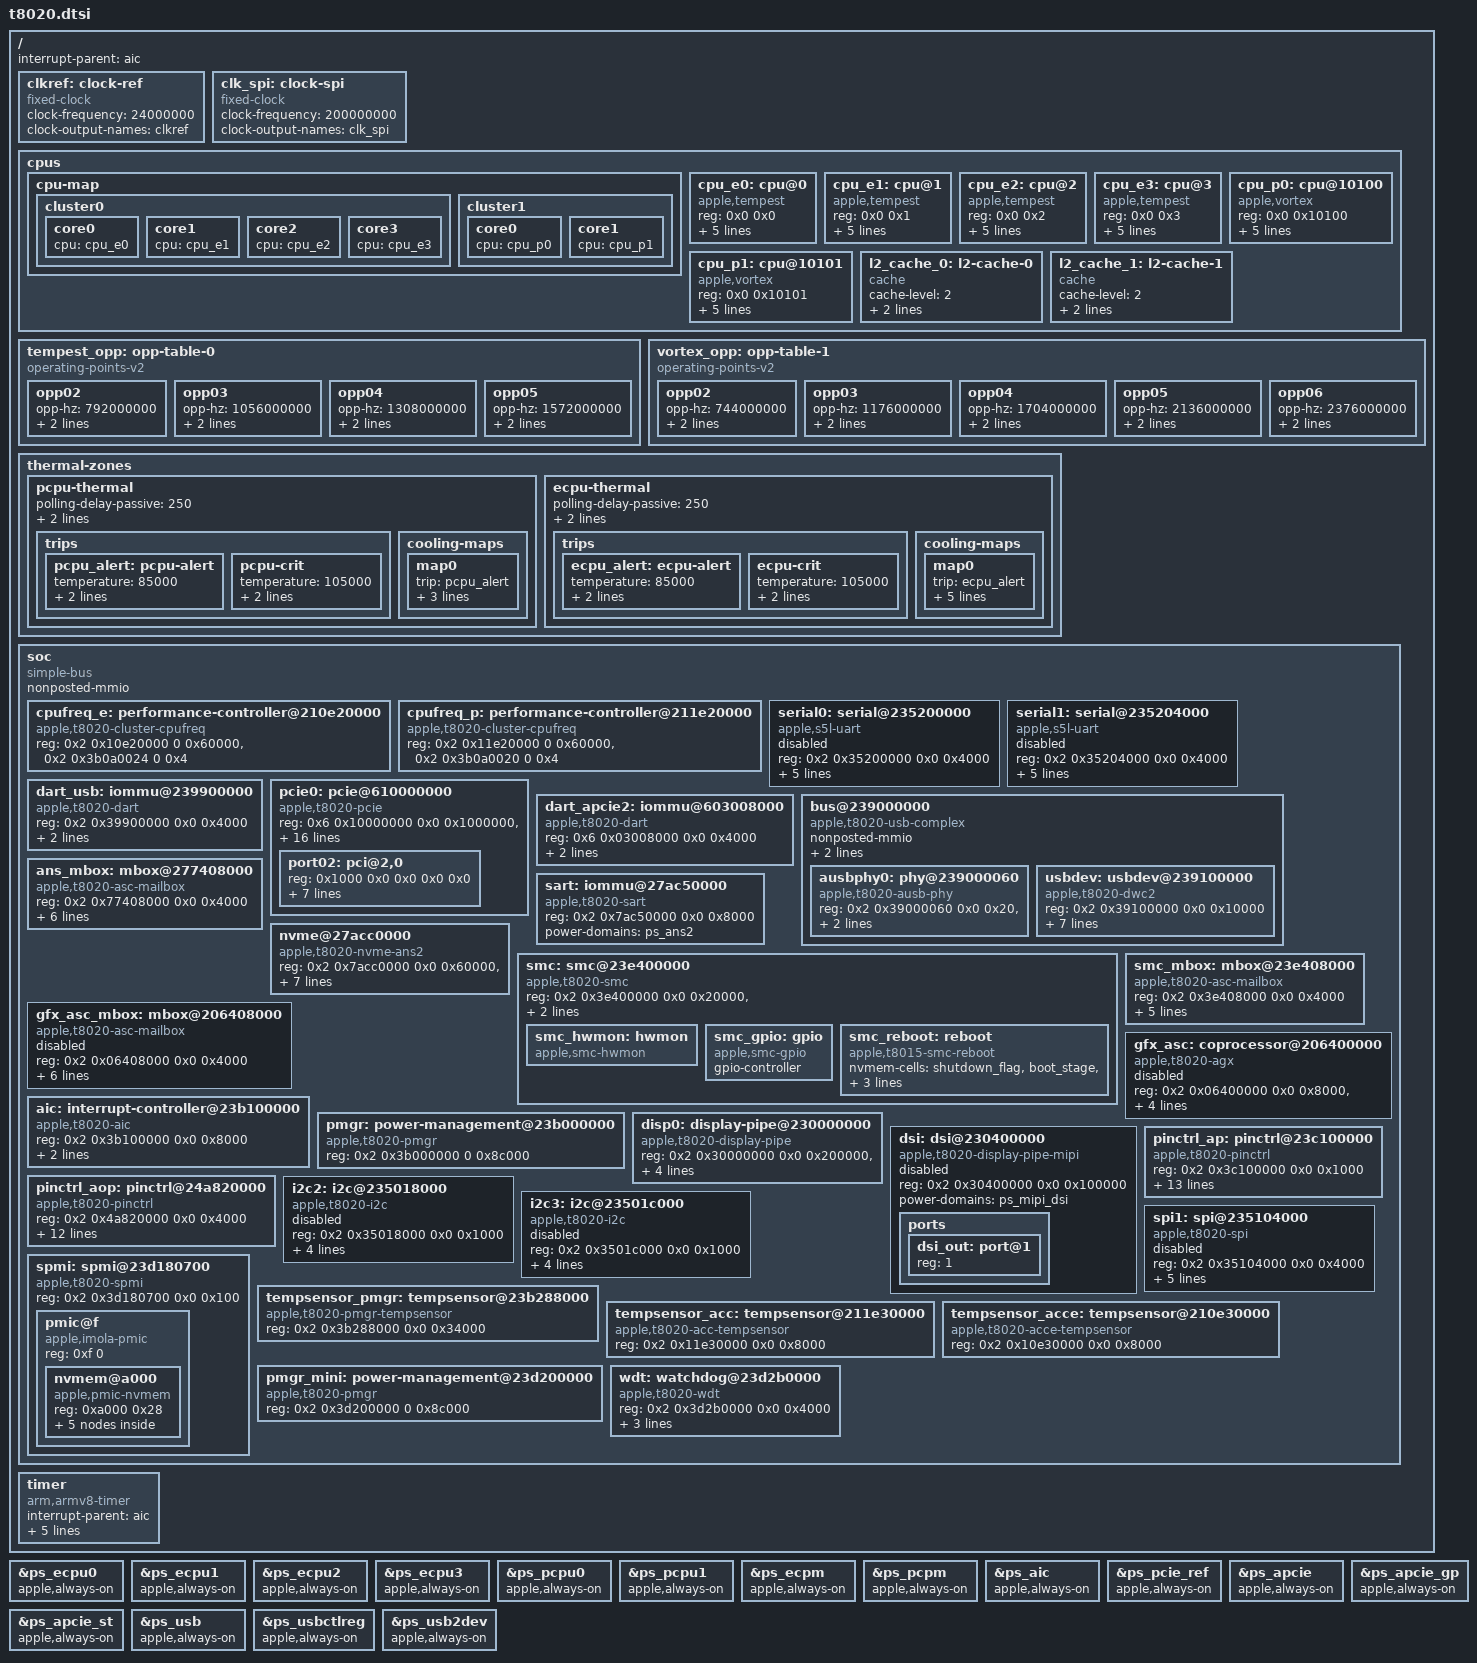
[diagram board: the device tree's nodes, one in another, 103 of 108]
// SPDX-License-Identifier: GPL-2.0+ OR MIT
/*
 * Apple T8020 "A12" SoC
 *
 * Other names: H11
 *
 * Every address and interrupt number here was read out of the DeviceTree
 * shipped in the iPhone11,2 IPSW (see docs/soc.md), not
 * guessed from T8015.
 * The arm-io ranges property maps child 0x0 to parent 0x200000000, so a
 * peripheral offset of 0x35200000 is absolute address 0x235200000.
 *
 * This is a bring-up subset: enough for a console, a shell and the pieces
 * being worked on, nothing more.
 *
 * Copyright (c) 2026, kiki <kieran@lavato.net>
 */

#include <dt-bindings/interrupt-controller/apple-aic.h>
#include <dt-bindings/interrupt-controller/irq.h>
#include <dt-bindings/phy/phy.h>
#include <dt-bindings/thermal/thermal.h>

/ {
	interrupt-parent = <&aic>;
	#address-cells = <2>;
	#size-cells = <2>;

	clkref: clock-ref {
		compatible = "fixed-clock";
		#clock-cells = <0>;
		clock-frequency = <24000000>;
		clock-output-names = "clkref";
	};

	/*
	 * The SPI blocks' input clock. The ADT gives it as clock-ids 362,
	 * which does not resolve to anything in the pmgr clock list, so this
	 * is M1's rate for the same block at the same address. If the real
	 * clock is slower the bus just runs slower than asked, never faster.
	 */
	clk_spi: clock-spi {
		compatible = "fixed-clock";
		#clock-cells = <0>;
		clock-frequency = <200000000>;
		clock-output-names = "clk_spi";
	};

	cpus {
		#address-cells = <2>;
		#size-cells = <0>;

		cpu-map {
			cluster0 {
				core0 {
					cpu = <&cpu_e0>;
				};
				core1 {
					cpu = <&cpu_e1>;
				};
				core2 {
					cpu = <&cpu_e2>;
				};
				core3 {
					cpu = <&cpu_e3>;
				};
			};

			cluster1 {
				core0 {
					cpu = <&cpu_p0>;
				};
				core1 {
					cpu = <&cpu_p1>;
				};
			};
		};

		/*
		 * These must equal MPIDR_EL1 & 0xFFFFFF, which is what m1n1's
		 * dt_set_cpus matches against, and get it wrong and m1n1 refuses
		 * to boot at all ("FDT: DT CPU 0 MPIDR mismatch: 0x10000 != 0x0").
		 * The ADT's reg is not that value. It reports 0 to 3 for the
		 * E cores and 256 and 257 for the P cores, while the hardware
		 * reads 0x0 to 0x3 and 0x10100 and 0x10101: the P cluster
		 * carries Aff2 as well as Aff1, the same scheme as M1. Read with
		 * the m1n1 proxy and from m1n1's own handoff log.
		 */
		cpu_e0: cpu@0 {
			compatible = "apple,tempest";
			reg = <0x0 0x0>;
			cpu-release-addr = <0 0>; /* To be filled by loader */
			performance-domains = <&cpufreq_e>;
			operating-points-v2 = <&tempest_opp>;
			#cooling-cells = <2>;
			enable-method = "spin-table";
			device_type = "cpu";
			next-level-cache = <&l2_cache_0>;
		};

		cpu_e1: cpu@1 {
			compatible = "apple,tempest";
			reg = <0x0 0x1>;
			cpu-release-addr = <0 0>; /* To be filled by loader */
			performance-domains = <&cpufreq_e>;
			operating-points-v2 = <&tempest_opp>;
			#cooling-cells = <2>;
			enable-method = "spin-table";
			device_type = "cpu";
			next-level-cache = <&l2_cache_0>;
		};

		cpu_e2: cpu@2 {
			compatible = "apple,tempest";
			reg = <0x0 0x2>;
			cpu-release-addr = <0 0>; /* To be filled by loader */
			performance-domains = <&cpufreq_e>;
			operating-points-v2 = <&tempest_opp>;
			#cooling-cells = <2>;
			enable-method = "spin-table";
			device_type = "cpu";
			next-level-cache = <&l2_cache_0>;
		};

		cpu_e3: cpu@3 {
			compatible = "apple,tempest";
			reg = <0x0 0x3>;
			cpu-release-addr = <0 0>; /* To be filled by loader */
			performance-domains = <&cpufreq_e>;
			operating-points-v2 = <&tempest_opp>;
			#cooling-cells = <2>;
			enable-method = "spin-table";
			device_type = "cpu";
			next-level-cache = <&l2_cache_0>;
		};

		cpu_p0: cpu@10100 {
			compatible = "apple,vortex";
			reg = <0x0 0x10100>;
			cpu-release-addr = <0 0>; /* To be filled by loader */
			performance-domains = <&cpufreq_p>;
			operating-points-v2 = <&vortex_opp>;
			#cooling-cells = <2>;
			enable-method = "spin-table";
			device_type = "cpu";
			next-level-cache = <&l2_cache_1>;
		};

		cpu_p1: cpu@10101 {
			compatible = "apple,vortex";
			reg = <0x0 0x10101>;
			cpu-release-addr = <0 0>; /* To be filled by loader */
			performance-domains = <&cpufreq_p>;
			operating-points-v2 = <&vortex_opp>;
			#cooling-cells = <2>;
			enable-method = "spin-table";
			device_type = "cpu";
			next-level-cache = <&l2_cache_1>;
		};

		/* Sizes come from the l2-cache-size property in the iOS DeviceTree. */
		l2_cache_0: l2-cache-0 {
			compatible = "cache";
			cache-level = <2>;
			cache-unified;
			cache-size = <0x200000>;
		};

		l2_cache_1: l2-cache-1 {
			compatible = "cache";
			cache-level = <2>;
			cache-unified;
			cache-size = <0x800000>;
		};
	};

	/*
	 * Frequencies are what iBoot fills into voltage-states1-sram (E) and
	 * voltage-states5-sram (P) in the live DeviceTree. The IPSW copies are
	 * zeroed. opp-level is the pstate, latencies are A11's.
	 *
	 * Pstate 1, 528 MHz on E and 504 MHz on P, is left out: a switch to it
	 * reaches it but leaves BUSY set in the cluster's CMD for good. P
	 * pstates 7 and 8, 2436 and 2496 MHz, are boost and left out too.
	 */
	tempest_opp: opp-table-0 {
		compatible = "operating-points-v2";
		opp02 {
			opp-hz = /bits/ 64 <792000000>;
			opp-level = <2>;
			clock-latency-ns = <140000>;
		};
		opp03 {
			opp-hz = /bits/ 64 <1056000000>;
			opp-level = <3>;
			clock-latency-ns = <105000>;
		};
		opp04 {
			opp-hz = /bits/ 64 <1308000000>;
			opp-level = <4>;
			clock-latency-ns = <115000>;
		};
		opp05 {
			opp-hz = /bits/ 64 <1572000000>;
			opp-level = <5>;
			clock-latency-ns = <125000>;
		};
	};

	vortex_opp: opp-table-1 {
		compatible = "operating-points-v2";
		opp02 {
			opp-hz = /bits/ 64 <744000000>;
			opp-level = <2>;
			clock-latency-ns = <140000>;
		};
		opp03 {
			opp-hz = /bits/ 64 <1176000000>;
			opp-level = <3>;
			clock-latency-ns = <110000>;
		};
		opp04 {
			opp-hz = /bits/ 64 <1704000000>;
			opp-level = <4>;
			clock-latency-ns = <110000>;
		};
		opp05 {
			opp-hz = /bits/ 64 <2136000000>;
			opp-level = <5>;
			clock-latency-ns = <125000>;
		};
		opp06 {
			opp-hz = /bits/ 64 <2376000000>;
			opp-level = <6>;
			clock-latency-ns = <130000>;
		};
	};

	/*
	 * Nothing else throttles the CPUs. Under full load the P cluster went
	 * from 69 to 82 C in 24 s. The sensors have no interrupt, so the zones
	 * poll. Channel 0 of each CPU block is the cluster sensor.
	 *
	 * The die sensor answers within a poll: one step down from 2376 MHz
	 * drops it by about 10 C. With a small hysteresis step_wise lets go on
	 * the next poll and P runs at full speed most of the time, so the
	 * hysteresis is wider than that swing.
	 */
	thermal-zones {
		pcpu-thermal {
			polling-delay-passive = <250>;
			polling-delay = <1000>;
			thermal-sensors = <&tempsensor_acc 0>;

			trips {
				pcpu_alert: pcpu-alert {
					temperature = <85000>;
					hysteresis = <10000>;
					type = "passive";
				};

				pcpu-crit {
					temperature = <105000>;
					hysteresis = <0>;
					type = "critical";
				};
			};

			cooling-maps {
				map0 {
					trip = <&pcpu_alert>;
					cooling-device =
						<&cpu_p0 THERMAL_NO_LIMIT THERMAL_NO_LIMIT>,
						<&cpu_p1 THERMAL_NO_LIMIT THERMAL_NO_LIMIT>;
				};
			};
		};

		ecpu-thermal {
			polling-delay-passive = <250>;
			polling-delay = <1000>;
			thermal-sensors = <&tempsensor_acce 0>;

			trips {
				ecpu_alert: ecpu-alert {
					temperature = <85000>;
					hysteresis = <10000>;
					type = "passive";
				};

				ecpu-crit {
					temperature = <105000>;
					hysteresis = <0>;
					type = "critical";
				};
			};

			cooling-maps {
				map0 {
					trip = <&ecpu_alert>;
					cooling-device =
						<&cpu_e0 THERMAL_NO_LIMIT THERMAL_NO_LIMIT>,
						<&cpu_e1 THERMAL_NO_LIMIT THERMAL_NO_LIMIT>,
						<&cpu_e2 THERMAL_NO_LIMIT THERMAL_NO_LIMIT>,
						<&cpu_e3 THERMAL_NO_LIMIT THERMAL_NO_LIMIT>;
				};
			};
		};
	};

	soc {
		compatible = "simple-bus";
		#address-cells = <2>;
		#size-cells = <2>;
		nonposted-mmio;
		ranges;

		/*
		 * The cluster DVFS blocks. The first reg reaches the pstate
		 * table 0x50000 up, whose rows carry each pstate's voltage.
		 * The second is the cluster's rail in the PMGR voltage block,
		 * which m1n1 hands to software.
		 */
		cpufreq_e: performance-controller@210e20000 {
			compatible = "apple,t8020-cluster-cpufreq",
				     "apple,t8103-cluster-cpufreq",
				     "apple,cluster-cpufreq";
			reg = <0x2 0x10e20000 0 0x60000>,
			      <0x2 0x3b0a0024 0 0x4>;
			#performance-domain-cells = <0>;
		};

		cpufreq_p: performance-controller@211e20000 {
			compatible = "apple,t8020-cluster-cpufreq",
				     "apple,t8103-cluster-cpufreq",
				     "apple,cluster-cpufreq";
			reg = <0x2 0x11e20000 0 0x60000>,
			      <0x2 0x3b0a0020 0 0x4>;
			#performance-domain-cells = <0>;
		};

		/* iBoot calls this one debug-console and leaves it running. */
		serial0: serial@235200000 {
			compatible = "apple,s5l-uart";
			reg = <0x2 0x35200000 0x0 0x4000>;
			reg-io-width = <4>;
			interrupt-parent = <&aic>;
			interrupts = <AIC_IRQ 386 IRQ_TYPE_LEVEL_HIGH>;
			/* Use the bootloader-enabled clocks for now. */
			clocks = <&clkref>, <&clkref>;
			clock-names = "uart", "clk_uart_baud0";
			power-domains = <&ps_uart0>;
			status = "disabled";
		};

		/* N841's /arm-io/uart1 hosts the N88 Bluetooth controller. */
		serial1: serial@235204000 {
			compatible = "apple,s5l-uart";
			reg = <0x2 0x35204000 0x0 0x4000>;
			reg-io-width = <4>;
			interrupt-parent = <&aic>;
			interrupts = <AIC_IRQ 387 IRQ_TYPE_LEVEL_HIGH>;
			clocks = <&clkref>, <&clkref>;
			clock-names = "uart", "clk_uart_baud0";
			power-domains = <&ps_uart1>;
			status = "disabled";
		};

		/*
		 * USB device mode. This is what gives an interactive shell:
		 * the initramfs brings up a CDC-ACM gadget, which shows up as
		 * /dev/ttyACM0 on the host. Without it the framebuffer console
		 * can print but you have nothing to type on.
		 *
		 * DMA is where this fell over, and dart_usb below is why. The
		 * ADT says it outright: /arm-io/usb-complex/usb-device has an
		 * iommu-parent pointing at /arm-io/dart-usb/mapper-usbdev,
		 * stream 0. There is no bypass to leave that DART in. Bypassed,
		 * the controller takes an AHB error on every DMA, which reaches
		 * the host as "device descriptor read/64, error -110", and
		 * m1n1's own gadget fails the same way on the same boot.
		 *
		 * The dma-ranges that used to be here, mapping DMA address 0 to
		 * the start of DRAM the way T8015 does, is gone with it. That
		 * translation is the DART's job now, and a dma-ranges offset on
		 * an IOMMU translated device only confuses the DMA layer.
		 */
		/*
		 * Stream 0 is the device controller, 1 is EHCI and 2 is OHCI,
		 * from the mapper nodes under /arm-io/dart-usb in the ADT.
		 *
		 * No power-domains. The gate the ADT names, clock-gates 0xb1,
		 * is not one of the power domains in t8020-pmgr.dtsi, so there
		 * is nothing to point at and nothing that can switch it off
		 * either. m1n1 powers it with pmgr_adt_power_enable() and
		 * leaves it on, which is what the ADT asks for.
		 *
		 * apple,t8103-dart is the compatible the driver binds: it has
		 * no entry for this SoC, and a T8020 DART is the same hardware,
		 * 32 bit in and 36 bit out, which is exactly what is needed
		 * here. dwc2 is a 32 bit master, so every address it emits fits
		 * the input side, and the DART puts it anywhere in DRAM.
		 */
		dart_usb: iommu@239900000 {
			compatible = "apple,t8020-dart", "apple,t8103-dart";
			reg = <0x2 0x39900000 0x0 0x4000>;
			interrupt-parent = <&aic>;
			interrupts = <AIC_IRQ 454 IRQ_TYPE_LEVEL_HIGH>;
			#iommu-cells = <1>;
		};

		/*
		 * PCIe. m1n1 powers it and applies the tunables iBoot leaves in
		 * the live ADT, as on T8103, whose register layout this shares.
		 * Port 2 is N841's BCM4357-family Wi-Fi endpoint; Bluetooth is
		 * described separately below UART1. Port 3 is the baseband.
		 * The ADT's 64 bit window overlaps its 32 bit one, so it is cut
		 * short here.
		 */
		pcie0: pcie@610000000 {
			compatible = "apple,t8020-pcie", "apple,pcie";
			device_type = "pci";

			/*
			 * Only port 2 is in use. Its PHY glue sits at rc + 0x88000
			 * + 0x4000 * port, one slot past where the driver assumes
			 * for T8103, so it is given here.
			 */
			reg = <0x6 0x10000000 0x0 0x1000000>,
			      <0x6 0x00000000 0x0 0x80000>,
			      <0x6 0x03000000 0x0 0x4000>,
			      <0x6 0x00090000 0x0 0x4000>;
			reg-names = "config", "rc", "port2", "phy2";

			interrupt-parent = <&aic>;
			interrupts = <AIC_IRQ 468 IRQ_TYPE_LEVEL_HIGH>,
				     <AIC_IRQ 471 IRQ_TYPE_LEVEL_HIGH>,
				     <AIC_IRQ 474 IRQ_TYPE_LEVEL_HIGH>,
				     <AIC_IRQ 477 IRQ_TYPE_LEVEL_HIGH>;

			msi-controller;
			msi-parent = <&pcie0>;
			msi-ranges = <&aic AIC_IRQ 480 IRQ_TYPE_EDGE_RISING 32>;

			iommu-map = <0x100 &dart_apcie2 0 1>;
			iommu-map-mask = <0xff00>;

			bus-range = <0 4>;
			#address-cells = <3>;
			#size-cells = <2>;
			ranges = <0x43000000 0x6 0x20000000 0x6 0x20000000 0x0 0x20000000>,
				 <0x02000000 0x0 0x40000000 0x6 0x40000000 0x0 0x40000000>;

			power-domains = <&ps_apcie_gp>;

			port02: pci@2,0 {
				device_type = "pci";
				reg = <0x1000 0x0 0x0 0x0 0x0>;
				/* function-perst in the ADT. CLKREQ#, pin 101, is muxed by iBoot. */
				reset-gpios = <&pinctrl_ap 106 1>;
				/* gP0e, function-reg_on of /amfm, the wifi REG_ON. */
				pwren-gpios = <&smc_gpio 14 0>;

				#address-cells = <3>;
				#size-cells = <2>;
				ranges;

				interrupt-controller;
				#interrupt-cells = <1>;

				interrupt-map-mask = <0 0 0 7>;
				interrupt-map = <0 0 0 1 &port02 0 0 0 0>,
						<0 0 0 2 &port02 0 0 0 1>,
						<0 0 0 3 &port02 0 0 0 2>,
						<0 0 0 4 &port02 0 0 0 3>;
			};
		};

		dart_apcie2: iommu@603008000 {
			compatible = "apple,t8020-dart", "apple,t8103-dart";
			reg = <0x6 0x03008000 0x0 0x4000>;
			interrupt-parent = <&aic>;
			interrupts = <AIC_IRQ 475 IRQ_TYPE_LEVEL_HIGH>;
			#iommu-cells = <1>;
		};

		bus@239000000 {
			compatible = "apple,t8020-usb-complex", "simple-pm-bus";
			#address-cells = <2>;
			#size-cells = <2>;

			/*
			 * of_mmio_is_nonposted() only looks at the node and its
			 * immediate parent, so the one on the soc node does not
			 * reach anything a bus further down. Without it here the
			 * PHY and dwc2 are mapped with ioremap() instead of
			 * ioremap_np(), and dwc2 then answers every read while
			 * dropping every write. Upstream repeats this property
			 * on the same bus for every A series SoC.
			 */
			nonposted-mmio;
			ranges;

			reg = <0x2 0x39000000 0x0 0x100>;
			power-domains = <&ps_usb>;

			ausbphy0: phy@239000060 {
				compatible = "apple,t8020-ausb-phy", "apple,ausb-phy";
				/* The PHY, and the USB complex registers before it. */
				reg = <0x2 0x39000060 0x0 0x20>,
				      <0x2 0x39000000 0x0 0x60>;
				power-domains = <&ps_usbctlreg>;
				#phy-cells = <1>;
				/* Tunables to be filled by loader */
			};

			usbdev: usbdev@239100000 {
				compatible = "apple,t8020-dwc2", "apple,dwc2";
				reg = <0x2 0x39100000 0x0 0x10000>;
				interrupts = <AIC_IRQ 451 IRQ_TYPE_LEVEL_HIGH>;
				clocks = <&clkref>;
				clock-names = "otg";
				phys = <&ausbphy0 PHY_TYPE_USB2>;
				phy-names = "usb2-phy";
				power-domains = <&ps_usb2dev>;
				resets = <&ps_usb2dev>;
				iommus = <&dart_usb 0>;
				dr_mode = "peripheral";
			};
		};

		/*
		 * NVMe, which on this SoC means the ANS2 coprocessor rather
		 * than a PCIe controller. Every number here comes from
		 * /arm-io/ans and /arm-io/sart-ans in the IPSW DeviceTree.
		 *
		 * The ADT gives /arm-io/ans nine reg ranges. Two are wanted:
		 * index 0 is the ASC wrapper and index 3 is the NVMe register
		 * block. The wrapper carries both the mailbox, at +0x8000, and
		 * the coprocessor control register at +0x44, which is the
		 * arrangement T8103 uses rather than the split one T8015 has.
		 * Confirmed on the hardware: writing bit 4 of 0x277400044 starts
		 * ANS and it puts a message in the inbound queue.
		 *
		 * The ADT also lists a lone four byte range at 0x27ad20044, which
		 * looks like a second copy of the same control register and
		 * accepts the write without starting anything. Pointing the node
		 * at it instead probes cleanly and then fails with "ANS did not
		 * boot". It is a decoy.
		 *
		 * The ADT lists five interrupts and says nvme-interrupt-idx is
		 * 4, so 371 is NVMe and the first four belong to the mailbox.
		 * The ADT order is 365, 364, 367, 366, which is two descending
		 * pairs rather than the order the binding wants. Read each pair
		 * as (not-empty, empty) and it comes out ascending, which is
		 * also how every other Apple SoC spells it, so that is what is
		 * used below. Taking the ADT order literally instead puts
		 * recv-not-empty on 366 and no mailbox interrupt ever arrives.
		 *
		 * The mailbox is the T8015 kind, not the v4 kind, even though
		 * the control register sits where T8103 puts it. The two
		 * layouts put their queue control registers in different
		 * places, 0x108 and 0x10c against 0x110 and 0x114, and on this
		 * SoC only the first pair is live: 0x108 reads 0x00020001 with
		 * the empty bit set, 0x110 and 0x114 read zero always. Claiming
		 * v4 here makes the driver poll two registers that never
		 * change, so the RTKit handshake times out and NVMe fails with
		 * "ANS did not boot" even though the coprocessor started.
		 */
		ans_mbox: mbox@277408000 {
			compatible = "apple,t8020-asc-mailbox", "apple,t8015-asc-mailbox";
			reg = <0x2 0x77408000 0x0 0x4000>;
			interrupt-parent = <&aic>;
			interrupts = <AIC_IRQ 364 IRQ_TYPE_LEVEL_HIGH>,
				     <AIC_IRQ 365 IRQ_TYPE_LEVEL_HIGH>,
				     <AIC_IRQ 366 IRQ_TYPE_LEVEL_HIGH>,
				     <AIC_IRQ 367 IRQ_TYPE_LEVEL_HIGH>;
			interrupt-names = "send-empty", "send-not-empty",
					  "recv-empty", "recv-not-empty";
			#mbox-cells = <0>;
			power-domains = <&ps_ans2>;
		};

		/*
		 * The ADT says sart-version = 1, which neither Linux nor m1n1
		 * has a case for: both know 0, 2 and 3 only. v0 and v2 share
		 * their register offsets and differ only in field widths, so
		 * the question is which one v1 resembles. The entries iBoot
		 * leaves behind answer it: one reads config 0x2f000004, and
		 * bit 29 is set, which does not fit v0's five bit flags field
		 * at 28:24 but does fit v2's eight bit field at 31:24. The size
		 * field decodes to 4 pages either way.
		 *
		 * v2 is also what gets furthest in practice: the coprocessor
		 * DMAs its syslog back, so the allowed regions it adds plainly
		 * work. Both v0 and v2 were first compared while the PCIe
		 * reference clock was still being switched off underneath
		 * them, so that earlier comparison proved nothing and was
		 * redone afterwards.
		 */
		sart: iommu@27ac50000 {
			compatible = "apple,t8020-sart";
			reg = <0x2 0x7ac50000 0x0 0x8000>;
			power-domains = <&ps_ans2>;
		};

		/*
		 * The driver has one variant for T8015, with no LSQ NVMMU and a
		 * queue depth of 16, and one for T8103 with both. T8015 is the
		 * one that gets furthest: the firmware boots, logs "boot mode
		 * normal" and starts reading NAND context. Claiming T8103
		 * instead goes back to crashing early.
		 *
		 * Treat that comparison as weak evidence though. The T8103 run
		 * reported the same PC and FAR as a crash from two boots
		 * earlier, so ANS looks like it keeps its crashlog across a
		 * reset and RTKit replays whatever it finds. Any single boot's
		 * crash dump may belong to a previous one.
		 */
		nvme@27acc0000 {
			compatible = "apple,t8020-nvme-ans2";
			reg = <0x2 0x7acc0000 0x0 0x60000>,
			      <0x2 0x77400000 0x0 0x4000>;
			reg-names = "nvme", "ans";
			interrupt-parent = <&aic>;
			interrupts = <AIC_IRQ 371 IRQ_TYPE_LEVEL_HIGH>;
			mboxes = <&ans_mbox>;
			apple,sart = <&sart>;
			power-domains = <&ps_ans2>, <&ps_apcie_st>;
			power-domain-names = "ans", "apcie0";
			resets = <&ps_ans2>;
		};

		/*
		 * The SMC, which owns the battery, the charger, the temperature
		 * sensors and the power button. Same RTKit over ASC mailbox
		 * shape as ANS, and the addresses line up with T8103 exactly:
		 * the ASC wrapper is at 0x23e400000 and the shared memory the
		 * ADT calls region-base on /arm-io/smc/iop-smc-nub is at
		 * 0x23fe00000, 0x50000 long.
		 *
		 * No power-domains. clock-gates and power-gates on the ADT node
		 * are both empty, which is what you would expect of the thing
		 * that runs when the rest of the SoC does not.
		 *
		 * apple,t8015-smc rather than the T8103 compatible, so the MFD
		 * instantiates the A11 cell list: input, power, gpio, hwmon and
		 * reboot, with no RTC. macsmc-power and macsmc-input need no
		 * node of their own.
		 */
		smc: smc@23e400000 {
			compatible = "apple,t8020-smc", "apple,t8015-smc",
				     "apple,t8103-smc";
			reg = <0x2 0x3e400000 0x0 0x20000>,
			      <0x2 0x3fe00000 0x0 0x50000>;
			reg-names = "smc", "sram";
			mboxes = <&smc_mbox>;

			smc_hwmon: hwmon {
				compatible = "apple,smc-hwmon";
			};

			/* The PMU's GPIOs, the SMC's gPxx keys. */
			smc_gpio: gpio {
				compatible = "apple,smc-gpio";
				gpio-controller;
				#gpio-cells = <2>;
			};

			/*
			 * Reboot and poweroff. The T8015 compatible is the one
			 * without the "phra" restart key, so a restart goes
			 * through the watchdog below and only poweroff is the
			 * SMC's job. The PMU cells are how the chip is told to
			 * stay off instead of coming straight back up.
			 */
			smc_reboot: reboot {
				compatible = "apple,t8015-smc-reboot";
				nvmem-cells = <&shutdown_flag>, <&boot_stage>,
					      <&boot_error_count>,
					      <&panic_count>;
				nvmem-cell-names = "shutdown_flag", "boot_stage",
						   "boot_error_count",
						   "panic_count";
			};
		};

		/*
		 * The ADT lists these as 254, 253, 256, 255, two descending
		 * pairs, exactly as it does for ANS. Read each pair as
		 * (not-empty, empty) and they come out ascending in the order
		 * the binding wants.
		 */
		smc_mbox: mbox@23e408000 {
			compatible = "apple,t8020-asc-mailbox",
				     "apple,t8015-asc-mailbox";
			reg = <0x2 0x3e408000 0x0 0x4000>;
			interrupt-parent = <&aic>;
			interrupts = <AIC_IRQ 253 IRQ_TYPE_LEVEL_HIGH>,
				     <AIC_IRQ 254 IRQ_TYPE_LEVEL_HIGH>,
				     <AIC_IRQ 255 IRQ_TYPE_LEVEL_HIGH>,
				     <AIC_IRQ 256 IRQ_TYPE_LEVEL_HIGH>;
			interrupt-names = "send-empty", "send-not-empty",
					  "recv-empty", "recv-not-empty";
			#mbox-cells = <0>;
		};

		/*
		 * The GPU's coprocessor. iBoot loads its firmware when sent one,
		 * and only then does m1n1 enable these two, so a boot without it
		 * is unchanged. agx-g11 boots the firmware and runs test kernels.
		 * The sgx (RGX) and fender ranges are only handed to the
		 * firmware, which maps them itself.
		 *
		 * The ADT lists the mailbox interrupts as 348, 347, 350, 349, the
		 * same descending pairs as ANS. ps_gfx is the one PMGR domain;
		 * the ADT's gates 208 to 210 are virtual devices under it.
		 */
		gfx_asc_mbox: mbox@206408000 {
			compatible = "apple,t8020-asc-mailbox",
				     "apple,t8015-asc-mailbox";
			reg = <0x2 0x06408000 0x0 0x4000>;
			interrupt-parent = <&aic>;
			interrupts = <AIC_IRQ 347 IRQ_TYPE_LEVEL_HIGH>,
				     <AIC_IRQ 348 IRQ_TYPE_LEVEL_HIGH>,
				     <AIC_IRQ 349 IRQ_TYPE_LEVEL_HIGH>,
				     <AIC_IRQ 350 IRQ_TYPE_LEVEL_HIGH>;
			interrupt-names = "send-empty", "send-not-empty",
					  "recv-empty", "recv-not-empty";
			#mbox-cells = <0>;
			power-domains = <&ps_gfx>;
			status = "disabled";
		};

		gfx_asc: coprocessor@206400000 {
			compatible = "apple,t8020-agx";
			reg = <0x2 0x06400000 0x0 0x8000>,
			      <0x2 0x04000000 0x0 0x20000>,
			      <0x2 0x04d00000 0x0 0x20000>;
			reg-names = "asc", "sgx", "fender";
			mboxes = <&gfx_asc_mbox>;
			power-domains = <&ps_gfx>;
			status = "disabled";
		};

		aic: interrupt-controller@23b100000 {
			compatible = "apple,t8020-aic", "apple,t8015-aic", "apple,aic";
			reg = <0x2 0x3b100000 0x0 0x8000>;
			#interrupt-cells = <3>;
			interrupt-controller;
			power-domains = <&ps_aic>;
		};

		pmgr: power-management@23b000000 {
			compatible = "apple,t8020-pmgr", "apple,pmgr", "syscon", "simple-mfd";
			#address-cells = <1>;
			#size-cells = <1>;

			reg = <0x2 0x3b000000 0 0x8c000>;
		};

		/*
		 * The display pipe iBoot leaves running. Two reg entries for
		 * one block: the window is mirrored every 0x200000 and only
		 * the second copy takes writes, so the driver reads through
		 * "read" and writes through "write". Reads work through
		 * either, which is what made this confusing to find.
		 *
		 * The two entries have to stop short of each other or the
		 * second request fails with EBUSY: the block is 0x2f0000 long
		 * and the mirror starts 0x200000 in, so they would overlap.
		 * Everything either view needs is in the first 0xf0000.
		 *
		 * iBoot leaves every disp0 domain on and the framebuffer node
		 * holds them while simpledrm runs. The driver evicts simpledrm,
		 * so it has to hold them itself first, and with links that are
		 * active, or they go off the moment simpledrm lets go.
		 *
		 * No dart-disp0 node, and that is not an omission. The ADT
		 * points disp0 at that DART, but its TTBRs are invalid by
		 * Apple's own test, bit 31 clear, which they could not be if
		 * the running scanout went through it. The surface register
		 * holds 32 bits and the framebuffer is at 0x8f7cd4000, so
		 * something ahead of the fetch supplies bits 35:32, the same
		 * way the USB complex remap widget does. So the driver writes
		 * physical addresses and no IOMMU is involved.
		 */
		disp0: display-pipe@230000000 {
			compatible = "apple,t8020-display-pipe";
			reg = <0x2 0x30000000 0x0 0x200000>,
			      <0x2 0x30200000 0x0 0xf0000>;
			reg-names = "read", "write";
			power-domains = <&ps_disp0_busif>, <&ps_disp0_fe>,
					<&ps_disp0_be>, <&ps_disp0_gp0>,
					<&ps_disp0_gp1>, <&ps_disp0_ppp>,
					<&ps_disp0_hilo>, <&ps_mipi_dsi>;
			power-domain-names = "busif", "fe", "be", "gp0",
					     "gp1", "ppp", "hilo", "mipi";
		};

		/*
		 * The DSI host, a Synopsys DesignWare core at the start of the
		 * window, the same one the M1 Touch Bar uses. AppleSynopsysMIPIDSI
		 * reads and writes the generic packet registers at 0x6c, 0x70 and
		 * 0x74 straight off the mapped base, which is all adp-mipi
		 * touches. iBoot has already configured the link, so this only
		 * ever sends commands. Nothing goes out until the panel's
		 * backlight is written.
		 *
		 * The input port is left out: there is no adp display pipe to
		 * connect it to, and adp-mipi only looks up port 1.
		 */
		dsi: dsi@230400000 {
			compatible = "apple,t8020-display-pipe-mipi",
				     "apple,h7-display-pipe-mipi";
			reg = <0x2 0x30400000 0x0 0x100000>;
			power-domains = <&ps_mipi_dsi>;
			#address-cells = <1>;
			#size-cells = <0>;
			status = "disabled";

			ports {
				#address-cells = <1>;
				#size-cells = <0>;

				dsi_out: port@1 {
					reg = <1>;
				};
			};
		};

		/*
		 * The AP GPIO block, gpio,t8020 in the ADT, 222 pins and seven
		 * interrupt groups. The driver writes nothing at probe, so
		 * pins iBoot set up stay as they are until someone asks for
		 * one. GPIO flags are written as numbers below, 0 for active
		 * high and 1 for active low, to avoid copying gpio.h in.
		 */
		pinctrl_ap: pinctrl@23c100000 {
			compatible = "apple,t8020-pinctrl", "apple,pinctrl";
			reg = <0x2 0x3c100000 0x0 0x1000>;
			power-domains = <&ps_gpio>;

			gpio-controller;
			#gpio-cells = <2>;
			gpio-ranges = <&pinctrl_ap 0 0 222>;
			apple,npins = <222>;

			interrupt-controller;
			#interrupt-cells = <2>;
			interrupt-parent = <&aic>;
			interrupts = <AIC_IRQ 95 IRQ_TYPE_LEVEL_HIGH>,
				     <AIC_IRQ 96 IRQ_TYPE_LEVEL_HIGH>,
				     <AIC_IRQ 97 IRQ_TYPE_LEVEL_HIGH>,
				     <AIC_IRQ 98 IRQ_TYPE_LEVEL_HIGH>,
				     <AIC_IRQ 99 IRQ_TYPE_LEVEL_HIGH>,
				     <AIC_IRQ 100 IRQ_TYPE_LEVEL_HIGH>,
				     <AIC_IRQ 101 IRQ_TYPE_LEVEL_HIGH>;
		};

		/*
		 * The AOP GPIO block, aop-gpio in the ADT, 52 pins. The ADT
		 * lists only groups 4 to 6 as supported, but group 0, which
		 * the driver uses, reaches AIC 176 all the same.
		 */
		pinctrl_aop: pinctrl@24a820000 {
			compatible = "apple,t8020-pinctrl", "apple,pinctrl";
			reg = <0x2 0x4a820000 0x0 0x4000>;

			gpio-controller;
			#gpio-cells = <2>;
			gpio-ranges = <&pinctrl_aop 0 0 52>;
			apple,npins = <52>;

			interrupt-controller;
			#interrupt-cells = <2>;
			interrupt-parent = <&aic>;
			interrupts = <AIC_IRQ 176 IRQ_TYPE_LEVEL_HIGH>,
				     <AIC_IRQ 177 IRQ_TYPE_LEVEL_HIGH>,
				     <AIC_IRQ 178 IRQ_TYPE_LEVEL_HIGH>,
				     <AIC_IRQ 179 IRQ_TYPE_LEVEL_HIGH>,
				     <AIC_IRQ 180 IRQ_TYPE_LEVEL_HIGH>,
				     <AIC_IRQ 181 IRQ_TYPE_LEVEL_HIGH>,
				     <AIC_IRQ 182 IRQ_TYPE_LEVEL_HIGH>;
		};

		/*
		 * The display PMU, Acorn, sits on this bus, and the touch
		 * controller's power comes from it. iBoot already talks to it,
		 * so the pins are muxed and there is no pinctrl here.
		 */
		i2c2: i2c@235018000 {
			compatible = "apple,t8020-i2c", "apple,i2c";
			reg = <0x2 0x35018000 0x0 0x1000>;
			clocks = <&clkref>;
			interrupt-parent = <&aic>;
			interrupts = <AIC_IRQ 410 IRQ_TYPE_LEVEL_HIGH>;
			power-domains = <&ps_i2c2>;
			#address-cells = <1>;
			#size-cells = <0>;
			status = "disabled";
		};

		i2c3: i2c@23501c000 {
			compatible = "apple,t8020-i2c", "apple,i2c";
			reg = <0x2 0x3501c000 0x0 0x1000>;
			clocks = <&clkref>;
			interrupt-parent = <&aic>;
			interrupts = <AIC_IRQ 411 IRQ_TYPE_LEVEL_HIGH>;
			power-domains = <&ps_i2c3>;
			#address-cells = <1>;
			#size-cells = <0>;
			status = "disabled";
		};

		/*
		 * The touch controller's bus. spi-1,samsung in the ADT: the
		 * older block M1's SPI grew out of, which spi-apple drives in a
		 * mode of its own. No "apple,spi" fallback, because the newer
		 * block's driver code would not work on it. See docs/touch.md.
		 * Chip select is a GPIO, as the ADT's function-spi_cs0 says.
		 * iBoot leaves pin 67 as an output driven high, which is the
		 * idle state the SPI core sets when it claims it.
		 */
		spi1: spi@235104000 {
			compatible = "apple,t8020-spi";
			reg = <0x2 0x35104000 0x0 0x4000>;
			interrupt-parent = <&aic>;
			interrupts = <AIC_IRQ 396 IRQ_TYPE_LEVEL_HIGH>;
			clocks = <&clk_spi>;
			power-domains = <&ps_spi1>;
			cs-gpios = <&pinctrl_ap 67 1>;
			#address-cells = <1>;
			#size-cells = <0>;
			status = "disabled";
		};

		/*
		 * The PMU side of the chip, reached over SPMI. The ADT node
		 * /arm-io/spmi lists three register ranges and a wall of
		 * interrupts; the driver only wants the first range.
		 *
		 * The PMIC is "pmu,imola" at slave id 0xf. Its scratchpad is
		 * the nvmem the reboot handler writes: the ADT calls the base
		 * info-leg_scrpad and puts it at 0xa000, with the regular
		 * scratchpad starting at 0xa028. Everything the reboot handler
		 * touches lives in those first 0x28 bytes, at the same offsets
		 * T8015 and T8103 use.
		 */
		spmi: spmi@23d180700 {
			compatible = "apple,t8020-spmi", "apple,t8103-spmi";
			reg = <0x2 0x3d180700 0x0 0x100>;
			#address-cells = <2>;
			#size-cells = <0>;

			pmic@f {
				compatible = "apple,imola-pmic",
					     "apple,spmi-pmic";
				/* second cell 0 is SPMI_USID */
				reg = <0xf 0>;
				#address-cells = <1>;
				#size-cells = <1>;

				nvmem@a000 {
					compatible = "apple,pmic-nvmem";
					reg = <0xa000 0x28>;

					nvmem-layout {
						compatible = "fixed-layout";
						#address-cells = <1>;
						#size-cells = <1>;

						boot_stage: boot-stage@1 {
							reg = <0x1 0x1>;
						};

						boot_error_count: boot-error-count@2,0 {
							reg = <0x2 0x1>;
							bits = <0 4>;
						};

						panic_count: panic-count@2,4 {
							reg = <0x2 0x1>;
							bits = <4 4>;
						};

						shutdown_flag: shutdown-flag@f {
							reg = <0xf 0x1>;
						};
					};
				};
			};
		};

		/*
		 * Die temperature sensors. The ADT has nine of them, all
		 * tempsensor,t8020, in three blocks: /arm-io/tempsensor0 to 4
		 * share one block in the power manager, 5 to 7 are the P
		 * cluster, and 8 is the E cluster. One node per block, because
		 * the sensors inside a block share a register range.
		 *
		 * The reg sizes cover the averaged reads as well, which sit
		 * 0x20000 up for the PMGR block and 0x4000 up for the clusters.
		 */
		tempsensor_pmgr: tempsensor@23b288000 {
			compatible = "apple,t8020-pmgr-tempsensor";
			reg = <0x2 0x3b288000 0x0 0x34000>;
		};

		tempsensor_acc: tempsensor@211e30000 {
			compatible = "apple,t8020-acc-tempsensor";
			reg = <0x2 0x11e30000 0x0 0x8000>;
			#thermal-sensor-cells = <1>;
		};

		tempsensor_acce: tempsensor@210e30000 {
			compatible = "apple,t8020-acce-tempsensor";
			reg = <0x2 0x10e30000 0x0 0x8000>;
			#thermal-sensor-cells = <1>;
		};

		pmgr_mini: power-management@23d200000 {
			compatible = "apple,t8020-pmgr", "apple,pmgr", "syscon", "simple-mfd";
			#address-cells = <1>;
			#size-cells = <1>;

			reg = <0x2 0x3d200000 0 0x8c000>;
		};

		wdt: watchdog@23d2b0000 {
			compatible = "apple,t8020-wdt", "apple,wdt";
			reg = <0x2 0x3d2b0000 0x0 0x4000>;
			clocks = <&clkref>;
			interrupt-parent = <&aic>;
			interrupts = <AIC_IRQ 232 IRQ_TYPE_LEVEL_HIGH>;
		};
	};

	timer {
		compatible = "arm,armv8-timer";
		interrupt-parent = <&aic>;
		interrupt-names = "phys", "virt", "hyp-phys", "hyp-virt";
		/* Unlike A11, the A12 does implement EL2, so wire the HV timers too. */
		interrupts = <AIC_FIQ AIC_TMR_GUEST_PHYS IRQ_TYPE_LEVEL_HIGH>,
			     <AIC_FIQ AIC_TMR_GUEST_VIRT IRQ_TYPE_LEVEL_HIGH>,
			     <AIC_FIQ AIC_TMR_HV_PHYS IRQ_TYPE_LEVEL_HIGH>,
			     <AIC_FIQ AIC_TMR_HV_VIRT IRQ_TYPE_LEVEL_HIGH>;
	};
};

#include "t8020-pmgr.dtsi"

/*
 * The CPU and CPU power manager domains, marked always-on as core devices the
 * same way upstream T8015 does. Without it "Disabling unused power domains"
 * tries to switch off the cluster the kernel is running on, which only
 * survives because the hardware refuses ("PS pcpu0: Failed to reach power
 * state 0x0"), and would take down any secondary m1n1 has already started.
 */
&ps_ecpu0 {
	apple,always-on;
};

&ps_ecpu1 {
	apple,always-on;
};

&ps_ecpu2 {
	apple,always-on;
};

&ps_ecpu3 {
	apple,always-on;
};

&ps_pcpu0 {
	apple,always-on;
};

&ps_pcpu1 {
	apple,always-on;
};

&ps_ecpm {
	apple,always-on;
};

&ps_pcpm {
	apple,always-on;
};

/*
 * Keep the interrupt controller powered.
 *
 * Nothing in Linux ever claims this domain. The AIC driver comes up through
 * IRQCHIP_DECLARE, which runs long before the driver model exists and never
 * creates a device, so there is no consumer for genpd to count. "PM: genpd:
 * Disabling unused power domains" then switches the controller off, and from
 * that point no interrupt is delivered and any read of an AIC register hangs
 * the core with no oops and no further output. The architected timer keeps
 * running through all of it because it is a core local FIQ that does not go
 * through AIC at all, so the boot reaches a shell looking healthy.
 *
 * Upstream marks this one always-on as a core device. The annotation is
 * missing here because t8020-pmgr.dtsi is generated by "make pmgr" from the
 * iOS DeviceTree, which has no equivalent property.
 */
&ps_aic {
	apple,always-on;
};

/*
 * Keep the PCIe reference clock powered.
 *
 * NVMe lives behind ANS2, and ANS2 reaches the storage link through the APCIe
 * block at 0x600080000. Nothing in this tree claims ps_pcie_ref: it has no
 * parent domain, and the nvme node names ps_ans2 and ps_apcie_st, whose own
 * parents genpd pulls up for it. So ps_pcie_ref is left with no users and
 * genpd switches it off, exactly as it did to the interrupt controller.
 *
 * The ANS firmware then takes an SError on 0x600084000, which is inside the
 * APCIe register window, and the driver reports "ANS did not boot" with a
 * crashlog whose FAR is that address.
 */
&ps_pcie_ref {
	apple,always-on;
};

/*
 * Keep the whole APCIe complex powered.
 *
 * The reference clock alone was not enough: the SError on 0x600084000 came
 * back intermittently, so one boot in two or three still lost the window
 * before ANS reached it. There is no apcie node in this tree, which means no
 * driver owns any of these domains. ps_apcie_st is the one the nvme node
 * names, and genpd pulls its parents ps_apcie and ps_imx up with it, but
 * ps_apcie_gp has no user at all and the whole set is at genpd's mercy for
 * ordering. Pinning all three takes the power manager out of the question;
 * iBoot has already trained the link by the time Linux starts, so nothing
 * here needs to bring the complex up, only to leave it alone.
 */
&ps_apcie {
	apple,always-on;
};

&ps_apcie_gp {
	apple,always-on;
};

&ps_apcie_st {
	apple,always-on;
};

/*
 * Keep the USB domains powered.
 *
 * dwc2 reads this controller fine but every write to it is dropped: GINTMSK,
 * DIEPMSK, GAHBCFG and DCTL all read back unchanged immediately after being
 * written, and GINTMSK and DIEPMSK read 0 even though the driver's own init
 * wrote them. Registers that keep their contents for reads but will not latch
 * a write are a block with no clock, which is what these domains gate.
 *
 * Nothing holds them up. drivers/usb/dwc2/platform.c uses no runtime PM at
 * all, and it calls dwc2_lowlevel_hw_disable() at the end of probe when
 * dr_mode is peripheral, so the domains are left to genpd, which powers down
 * whatever nothing has claimed.
 *
 * These overrides go here rather than in t8020-pmgr.dtsi because that file is
 * generated by "make pmgr" and edits to it do not survive.
 */
&ps_usb {
	apple,always-on;
};

&ps_usbctlreg {
	apple,always-on;
};

&ps_usb2dev {
	apple,always-on;
};
